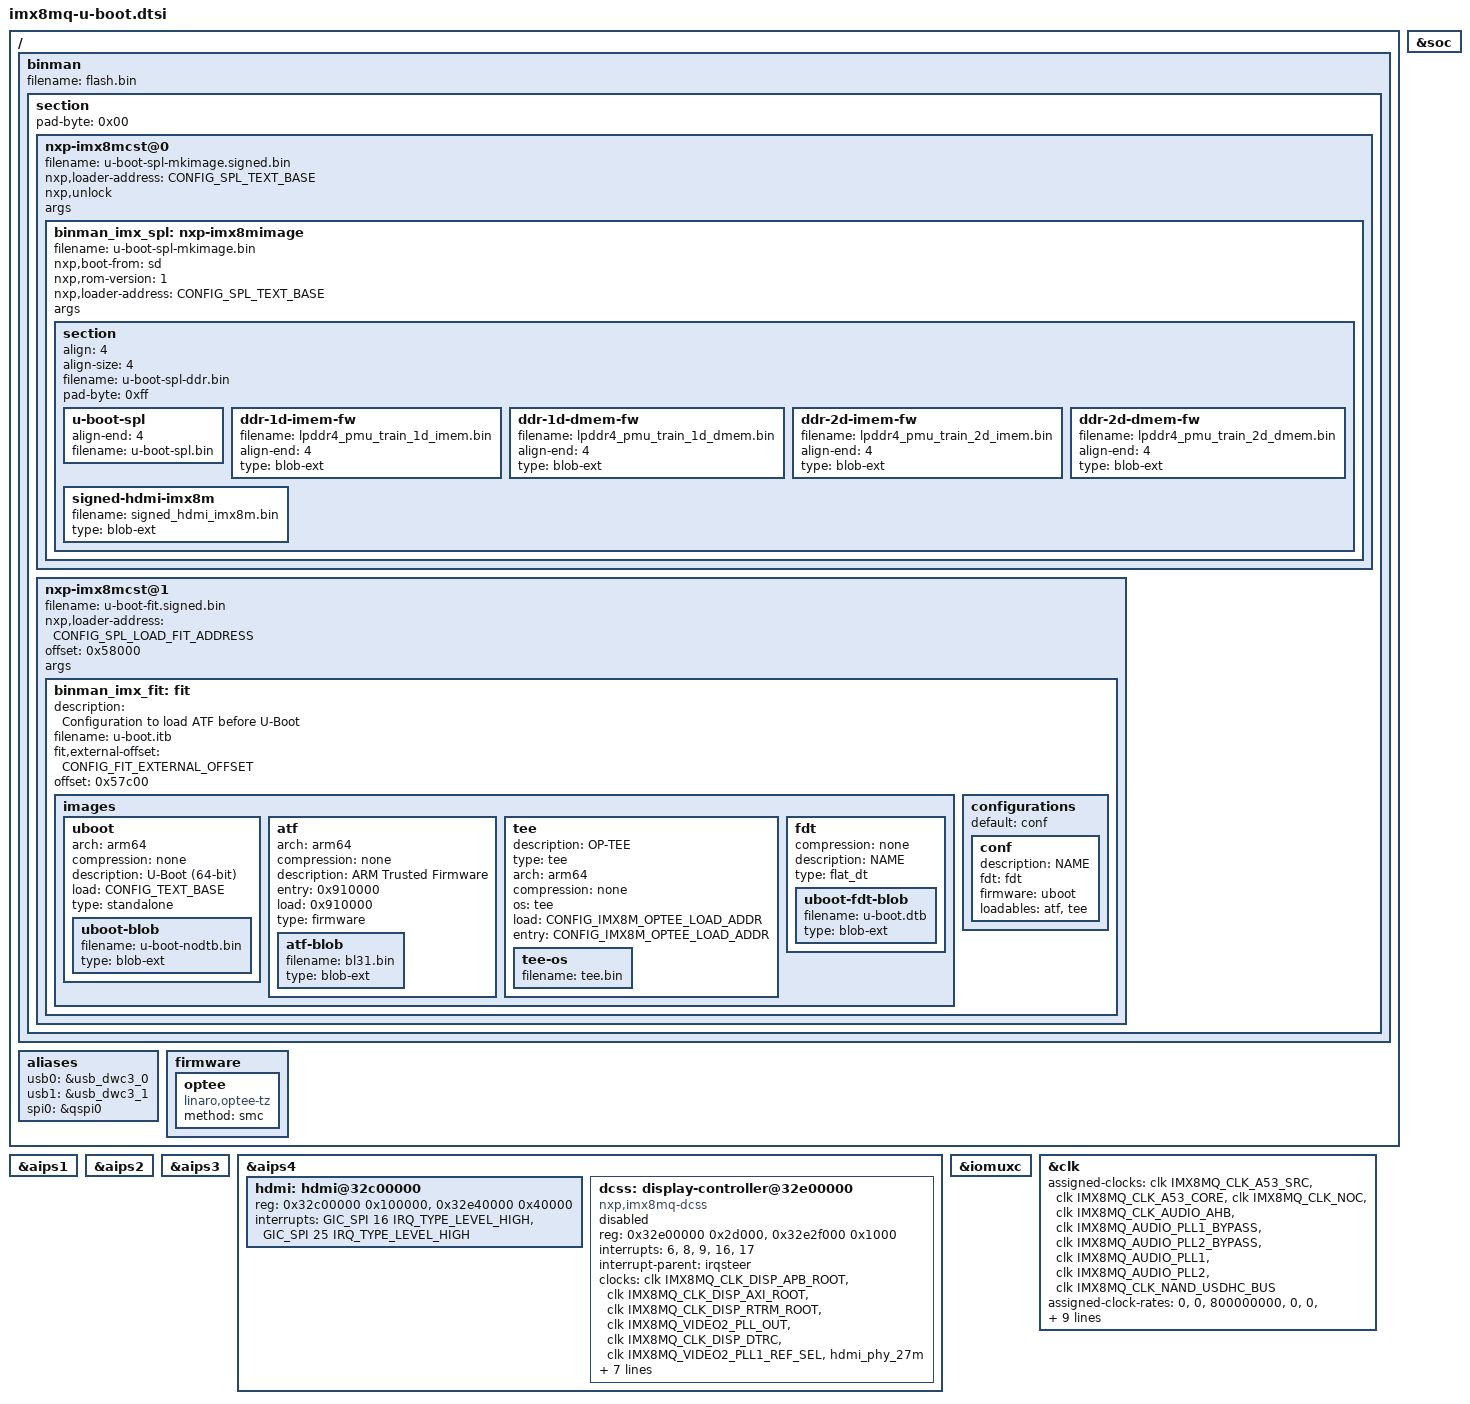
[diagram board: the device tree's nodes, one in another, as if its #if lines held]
// SPDX-License-Identifier: GPL-2.0+
/*
 * Copyright 2021 NXP
 */

/ {
	binman: binman {
	};

	aliases {
		usb0 = &usb_dwc3_0;
		usb1 = &usb_dwc3_1;
		spi0 = &qspi0;
	};

#ifdef CONFIG_OPTEE
	firmware {
		optee {
			compatible = "linaro,optee-tz";
			method = "smc";
		};
	};
#endif
};

&soc {
	bootph-pre-ram;
};

&aips1 {
	bootph-pre-ram;
};

&aips2 {
	bootph-pre-ram;
};

&aips3 {
	bootph-pre-ram;
};

&aips4 {
	bootph-pre-ram;
};

&iomuxc {
	bootph-pre-ram;
};

&clk{
	assigned-clocks = <&clk IMX8MQ_CLK_A53_SRC>,
				<&clk IMX8MQ_CLK_A53_CORE>,
				<&clk IMX8MQ_CLK_NOC>,
				<&clk IMX8MQ_CLK_AUDIO_AHB>,
				<&clk IMX8MQ_AUDIO_PLL1_BYPASS>,
				<&clk IMX8MQ_AUDIO_PLL2_BYPASS>,
				<&clk IMX8MQ_AUDIO_PLL1>,
				<&clk IMX8MQ_AUDIO_PLL2>,
				<&clk IMX8MQ_CLK_NAND_USDHC_BUS>;
	assigned-clock-rates = <0>, <0>,
			       <800000000>,
			       <0>,
			       <0>,
			       <0>,
			       <786432000>,
			       <722534400>,
			       <0>;
	assigned-clock-parents = <&clk IMX8MQ_SYS1_PLL_800M>,
				 <&clk IMX8MQ_ARM_PLL_OUT>,
				 <&clk IMX8MQ_SYS1_PLL_800M>,
				 <&clk IMX8MQ_SYS2_PLL_500M>,
				 <&clk IMX8MQ_AUDIO_PLL1>,
				 <&clk IMX8MQ_AUDIO_PLL2>,
				 <0>,
			         <0>,
				 <&clk IMX8MQ_SYS1_PLL_133M>;
};

&aips4 {
	hdmi: hdmi@32c00000 {
		reg = <0x32c00000 0x100000>,
			<0x32e40000 0x40000>;
		interrupts = <GIC_SPI 16 IRQ_TYPE_LEVEL_HIGH>,
			<GIC_SPI 25 IRQ_TYPE_LEVEL_HIGH>;
		interrupt-names = "plug_in", "plug_out";
	};

	dcss: display-controller@32e00000 {
		#address-cells = <1>;
		#size-cells = <0>;
		compatible = "nxp,imx8mq-dcss";
		reg = <0x32e00000 0x2d000>, <0x32e2f000 0x1000>;
		interrupts = <6>, <8>, <9>, <16>, <17>;
		interrupt-names = "ctxld", "ctxld_kick", "vblank",
						  "dtrc_ch1", "dtrc_ch2";
		interrupt-parent = <&irqsteer>;
		clocks = <&clk IMX8MQ_CLK_DISP_APB_ROOT>,
			 <&clk IMX8MQ_CLK_DISP_AXI_ROOT>,
			 <&clk IMX8MQ_CLK_DISP_RTRM_ROOT>,
			 <&clk IMX8MQ_VIDEO2_PLL_OUT>,
			 <&clk IMX8MQ_CLK_DISP_DTRC>,
			 <&clk IMX8MQ_VIDEO2_PLL1_REF_SEL>,
			 <&hdmi_phy_27m>;
		clock-names = "apb", "axi", "rtrm", "pix", "dtrc", "pll_src",
				      "pll_phy_ref";
		assigned-clocks = <&clk IMX8MQ_CLK_DISP_AXI>,
				  <&clk IMX8MQ_CLK_DISP_RTRM>,
				  <&clk IMX8MQ_VIDEO2_PLL1_REF_SEL>;
		assigned-clock-parents = <&clk IMX8MQ_SYS1_PLL_800M>,
					 <&clk IMX8MQ_SYS1_PLL_800M>,
					 <&clk IMX8MQ_CLK_27M>;
		assigned-clock-rates = <800000000>,
					   <400000000>;
		status = "disabled";
	};
};

&binman {
	filename = "flash.bin";
	section {
		pad-byte = <0x00>;

#ifdef CONFIG_IMX_HAB
		nxp-imx8mcst@0 {
			filename = "u-boot-spl-mkimage.signed.bin";
			nxp,loader-address = <CONFIG_SPL_TEXT_BASE>;
			nxp,unlock;
			args;	/* Needed by mkimage etype superclass */
#endif

			binman_imx_spl: nxp-imx8mimage {
				filename = "u-boot-spl-mkimage.bin";
				nxp,boot-from = "sd";
				nxp,rom-version = <1>;
				nxp,loader-address = <CONFIG_SPL_TEXT_BASE>;
				args;	/* Needed by mkimage etype superclass */

				section {
					align = <4>;
					align-size = <4>;
					filename = "u-boot-spl-ddr.bin";
					pad-byte = <0xff>;

					u-boot-spl {
						align-end = <4>;
						filename = "u-boot-spl.bin";
					};

					ddr-1d-imem-fw {
						filename = "lpddr4_pmu_train_1d_imem.bin";
						align-end = <4>;
						type = "blob-ext";
					};

					ddr-1d-dmem-fw {
						filename = "lpddr4_pmu_train_1d_dmem.bin";
						align-end = <4>;
						type = "blob-ext";
					};

					ddr-2d-imem-fw {
						filename = "lpddr4_pmu_train_2d_imem.bin";
						align-end = <4>;
						type = "blob-ext";
					};

					ddr-2d-dmem-fw {
						filename = "lpddr4_pmu_train_2d_dmem.bin";
						align-end = <4>;
						type = "blob-ext";
					};

					signed-hdmi-imx8m {
						filename = "signed_hdmi_imx8m.bin";
						type = "blob-ext";
					};
				};
			};
#ifdef CONFIG_IMX_HAB
		};

		nxp-imx8mcst@1 {
			filename = "u-boot-fit.signed.bin";
			nxp,loader-address = <CONFIG_SPL_LOAD_FIT_ADDRESS>;
			offset = <0x58000>;
			args;	/* Needed by mkimage etype superclass */
#endif

			binman_imx_fit: fit {
				description = "Configuration to load ATF before U-Boot";
				filename = "u-boot.itb";
#ifndef CONFIG_IMX_HAB
				fit,external-offset = <CONFIG_FIT_EXTERNAL_OFFSET>;
#endif
				#address-cells = <1>;

				offset = <0x57c00>;

				images {
					uboot {
						arch = "arm64";
						compression = "none";
						description = "U-Boot (64-bit)";
						load = <CONFIG_TEXT_BASE>;
						type = "standalone";

						uboot-blob {
							filename = "u-boot-nodtb.bin";
							type = "blob-ext";
						};
					};

#ifndef CONFIG_ARMV8_PSCI
					atf {
						arch = "arm64";
						compression = "none";
						description = "ARM Trusted Firmware";
						entry = <0x910000>;
						load = <0x910000>;
						type = "firmware";

						atf-blob {
							filename = "bl31.bin";
							type = "blob-ext";
						};
					};
#endif

#ifdef CONFIG_OPTEE
					tee: tee {
						description = "OP-TEE";
						type = "tee";
						arch = "arm64";
						compression = "none";
						os = "tee";
						load = <CONFIG_IMX8M_OPTEE_LOAD_ADDR>;
						entry = <CONFIG_IMX8M_OPTEE_LOAD_ADDR>;

						tee-os {
							filename = "tee.bin";
						};
					};
#endif

					fdt {
						compression = "none";
						description = "NAME";
						type = "flat_dt";

						uboot-fdt-blob {
							filename = "u-boot.dtb";
							type = "blob-ext";
						};
					};
				};

				configurations {
					default = "conf";

					conf {
						description = "NAME";
						fdt = "fdt";
						firmware = "uboot";
#ifndef CONFIG_ARMV8_PSCI
#ifdef CONFIG_OPTEE
						loadables = "atf", "tee";
#else
						loadables = "atf";
#endif
#endif
					};
				};
			};
#ifdef CONFIG_IMX_HAB
		};
#endif
	};
};
